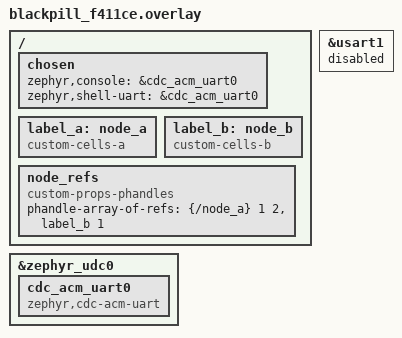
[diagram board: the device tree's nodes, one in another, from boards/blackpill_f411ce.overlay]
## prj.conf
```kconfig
CONFIG_GPIO=y
CONFIG_USB_DEVICE_STACK_NEXT=y
CONFIG_CDC_ACM_SERIAL_INITIALIZE_AT_BOOT=y
# CONFIG_USB_DEVICE_INITIALIZE_AT_BOOT=y
```

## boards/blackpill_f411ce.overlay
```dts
/ {
  chosen {
    zephyr,console = &cdc_acm_uart0;
    zephyr,shell-uart = &cdc_acm_uart0;
  };

  label_a: node_a { 
    compatible = "custom-cells-a";
    #phandle-array-of-ref-cells = <2>;
  };

  label_b: node_b { 
    compatible = "custom-cells-b";
    #phandle-array-of-ref-cells = <1>;
  };

  node_refs {
    compatible = "custom-props-phandles";
    phandle-array-of-refs = <&{/node_a} 1 2 &label_b 1>;
  };
};

&usart1 {
  status = "disabled";
};

&zephyr_udc0 {
  cdc_acm_uart0: cdc_acm_uart0 {
    compatible = "zephyr,cdc-acm-uart";
  };
};
```

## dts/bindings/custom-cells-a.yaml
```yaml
description: Dummy for matching "cells"
compatible: "custom-cells-a"

properties:
  "#phandle-array-of-ref-cells":
    type: int
    const: 2

phandle-array-of-ref-cells:
  - name-of-cell-one
  - name-of-cell-two
```

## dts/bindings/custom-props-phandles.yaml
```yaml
description: Custom properties
compatible: "custom-props-phandles"

properties:
  phandle-array-of-refs:
    type: phandle-array
```

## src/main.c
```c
/*
 * Copyright (c) 2016 Intel Corporation
 *
 * SPDX-License-Identifier: Apache-2.0
 */

#include <stdio.h>
#include <zephyr/drivers/gpio.h>
#include <zephyr/kernel.h>

/* 1000 msec = 1 sec */
#define SLEEP_TIME_MS 20

/* The devicetree node identifier for the "led0" alias. */
#define LED0_NODE DT_ALIAS(led0)

#define SW0_NODE DT_ALIAS(sw0)

/*
 * A build error on this line means your board is unsupported.
 * See the sample documentation for information on how to fix this.
 */
static const struct gpio_dt_spec led = GPIO_DT_SPEC_GET(LED0_NODE, gpios);

static const struct gpio_dt_spec btn = GPIO_DT_SPEC_GET(SW0_NODE, gpios);

typedef struct {
  uint32_t cell_one;
  uint32_t cell_two;
} node_spec_t;

#define NODE_DT_SPEC_GET_BY_IDX(node_id, prop, idx)                            \
  {.cell_one = DT_PHA_BY_IDX(node_id, prop, idx, name_of_cell_one),            \
   .cell_two = DT_PHA_BY_IDX_OR(node_id, prop, idx, name_of_cell_two, 0)}

node_spec_t node_a =
    NODE_DT_SPEC_GET_BY_IDX(DT_PATH(node_refs), phandle_array_of_refs, 0);

int main(void) {
  int ret, sw_state, prev_sw_state;
  prev_sw_state = 0;
  bool led_state = true;

  if (!gpio_is_ready_dt(&led) || !gpio_is_ready_dt(&btn)) {
    return 0;
  }

  ret = gpio_pin_configure_dt(&led, GPIO_OUTPUT_ACTIVE);
  if (ret < 0) {
    return 0;
  }

  ret = gpio_pin_configure_dt(&btn, GPIO_INPUT);
  if (ret < 0) {
    return 0;
  }

  while (1) {
    sw_state = gpio_pin_get_dt(&btn);
    if (ret < 0) {
      return 0;
    }
    if (sw_state && sw_state != prev_sw_state) {
      led_state = !led_state;
      ret = gpio_pin_set_dt(&led, led_state);
      if (ret < 0) {
        return 0;
      }
      printf("LED state: %s %d\n", led_state ? "ON" : "OFF",
             led_state ? node_a.cell_one : node_a.cell_two);
    }
    prev_sw_state = sw_state;

    k_msleep(SLEEP_TIME_MS);
  }
  return 0;
}
```
